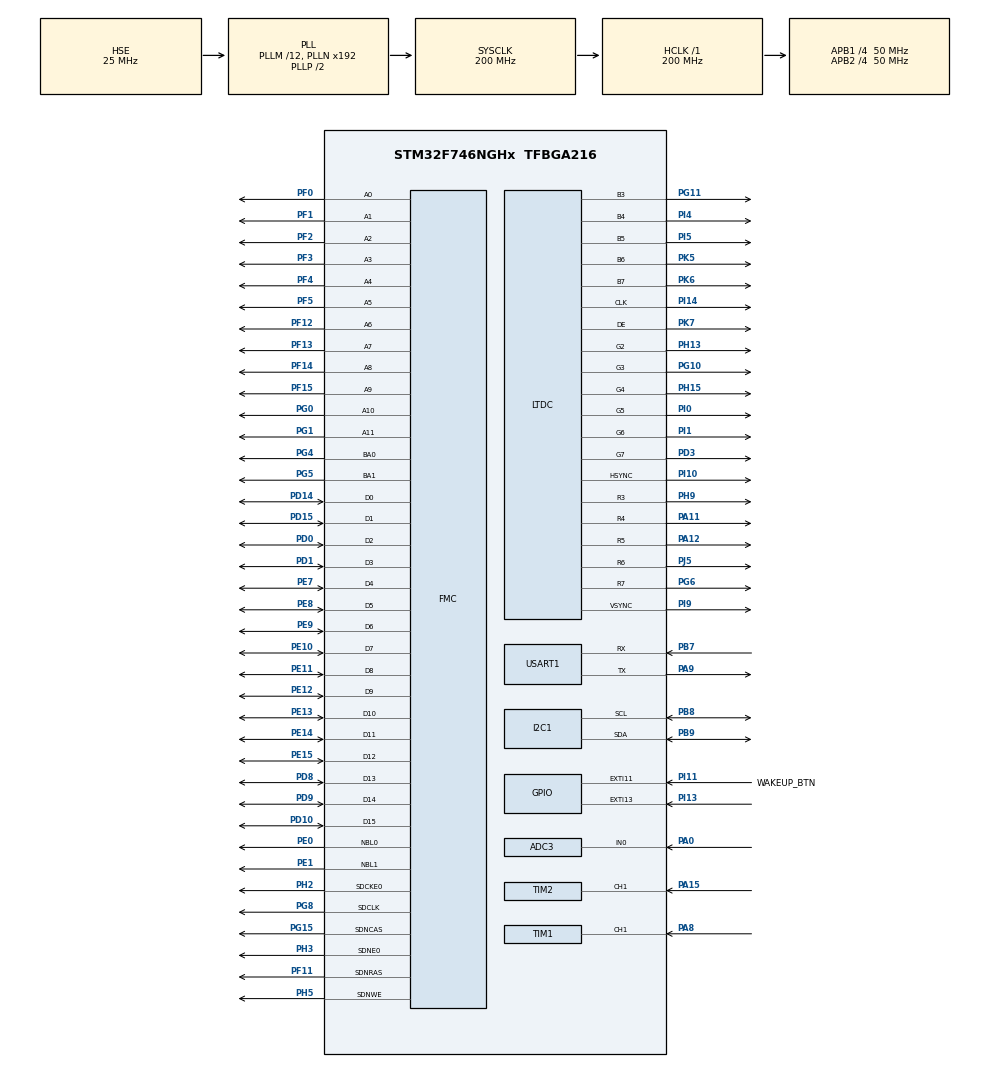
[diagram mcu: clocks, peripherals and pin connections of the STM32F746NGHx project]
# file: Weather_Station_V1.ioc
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ADC3.Channel-0\#ChannelRegularConversion=ADC_CHANNEL_0
ADC3.ClockPrescaler=ADC_CLOCK_SYNC_PCLK_DIV4
ADC3.ContinuousConvMode=ENABLE
ADC3.EOCSelection=ADC_EOC_SEQ_CONV
ADC3.NbrOfConversionFlag=1
ADC3.Rank-0\#ChannelRegularConversion=1
ADC3.SamplingTime-0\#ChannelRegularConversion=ADC_SAMPLETIME_3CYCLES
I2C1.Timing=0x00C0EAFF
Mcu.Family=STM32F7
Mcu.Name=STM32F746NGHx
Mcu.Package=TFBGA216
NVIC.ADC_IRQn=true\:0\:0\:false\:false\:true\:true\:true\:true
NVIC.EXTI15_10_IRQn=true\:0\:0\:false\:false\:true\:true\:true\:true
NVIC.PriorityGroup=NVIC_PRIORITYGROUP_4
NVIC.TIM1_CC_IRQn=true\:3\:0\:true\:false\:true\:true\:true\:true
NVIC.TIM2_IRQn=true\:2\:0\:true\:false\:true\:true\:true\:true
NVIC.TIM3_IRQn=true\:5\:0\:true\:false\:true\:true\:true\:true
NVIC.TIM6_DAC_IRQn=true\:1\:0\:true\:false\:true\:true\:true\:true
NVIC.TIM7_IRQn=true\:4\:0\:true\:false\:true\:true\:true\:true
PA0/WKUP.Signal=ADCx_IN0
PA11.Mode=RGB565
PA11.Signal=LTDC_R4
PA12.Mode=RGB565
PA12.Signal=LTDC_R5
PA13.Mode=Serial_Wire
PA13.Signal=SYS_JTMS-SWDIO
PA14.Mode=Serial_Wire
PA14.Signal=SYS_JTCK-SWCLK
PA15.Signal=S_TIM2_CH1_ETR
PA8.Signal=S_TIM1_CH1
PA9.Mode=Asynchronous
PA9.Signal=USART1_TX
PB7.Mode=Asynchronous
PB7.Signal=USART1_RX
PB8.Mode=I2C
PB8.Signal=I2C1_SCL
PB9.Mode=I2C
PB9.Signal=I2C1_SDA
PC14/OSC32_IN.Mode=LSE-External-Oscillator
PC14/OSC32_IN.Signal=RCC_OSC32_IN
PC15/OSC32_OUT.Mode=LSE-External-Oscillator
PC15/OSC32_OUT.Signal=RCC_OSC32_OUT
PD0.Signal=FMC_D2_DA2
PD1.Signal=FMC_D3_DA3
PD10.Signal=FMC_D15_DA15
PD14.Signal=FMC_D0_DA0
PD15.Signal=FMC_D1_DA1
PD3.Mode=RGB565
PD3.Signal=LTDC_G7
PD8.Signal=FMC_D13_DA13
PD9.Signal=FMC_D14_DA14
PE0.Signal=FMC_NBL0
PE1.Signal=FMC_NBL1
PE10.Signal=FMC_D7_DA7
PE11.Signal=FMC_D8_DA8
PE12.Signal=FMC_D9_DA9
PE13.Signal=FMC_D10_DA10
PE14.Signal=FMC_D11_DA11
PE15.Signal=FMC_D12_DA12
PE7.Signal=FMC_D4_DA4
PE8.Signal=FMC_D5_DA5
PE9.Signal=FMC_D6_DA6
PF0.Signal=FMC_A0
PF1.Signal=FMC_A1
PF11.Signal=FMC_SDNRAS
PF12.Signal=FMC_A6
PF13.Signal=FMC_A7
PF14.Signal=FMC_A8
PF15.Signal=FMC_A9
PF2.Signal=FMC_A2
PF3.Signal=FMC_A3
PF4.Signal=FMC_A4
PF5.Signal=FMC_A5
PG0.Signal=FMC_A10
PG1.Signal=FMC_A11
PG10.Mode=RGB565
PG10.Signal=LTDC_G3
PG11.Mode=RGB565
PG11.Signal=LTDC_B3
PG15.Signal=FMC_SDNCAS
PG4.Signal=FMC_A14_BA0
PG5.Signal=FMC_A15_BA1
PG6.Mode=RGB565
PG6.Signal=LTDC_R7
PG8.Signal=FMC_SDCLK
PH0/OSC_IN.Mode=HSE-External-Oscillator
PH0/OSC_IN.Signal=RCC_OSC_IN
PH1/OSC_OUT.Mode=HSE-External-Oscillator
PH1/OSC_OUT.Signal=RCC_OSC_OUT
PH13.Mode=RGB565
PH13.Signal=LTDC_G2
PH15.Mode=RGB565
PH15.Signal=LTDC_G4
PH2.Mode=SdramChipSelect1_1
PH2.Signal=FMC_SDCKE0
PH3.Mode=SdramChipSelect1_1
PH3.Signal=FMC_SDNE0
PH5.Signal=FMC_SDNWE
PH9.Mode=RGB565
PH9.Signal=LTDC_R3
PI0.Mode=RGB565
PI0.Signal=LTDC_G5
PI1.Mode=RGB565
PI1.Signal=LTDC_G6
PI10.Mode=RGB565
PI10.Signal=LTDC_HSYNC
PI11.GPIO_Label=WAKEUP_BTN
PI11.GPIO_ModeDefaultEXTI=GPIO_MODE_IT_RISING
PI11.GPIO_PuPd=GPIO_NOPULL
PI11.Signal=GPXTI11
PI13.GPIO_ModeDefaultEXTI=GPIO_MODE_IT_RISING_FALLING
PI13.GPIO_PuPd=GPIO_NOPULL
PI13.Signal=GPXTI13
PI14.Mode=RGB565
PI14.Signal=LTDC_CLK
PI4.Mode=RGB565
PI4.Signal=LTDC_B4
PI5.Mode=RGB565
PI5.Signal=LTDC_B5
PI9.Mode=RGB565
PI9.Signal=LTDC_VSYNC
PJ5.Mode=RGB565
PJ5.Signal=LTDC_R6
PK5.Mode=RGB565
PK5.Signal=LTDC_B6
PK6.Mode=RGB565
PK6.Signal=LTDC_B7
PK7.Mode=RGB565
PK7.Signal=LTDC_DE
ProjectManager.HeapSize=0x200
ProjectManager.StackSize=0x400
ProjectManager.TargetToolchain=STM32CubeIDE
RCC.AHBFreq_Value=200000000
RCC.APB1CLKDivider=RCC_HCLK_DIV4
RCC.APB1Freq_Value=50000000
RCC.APB1TimFreq_Value=100000000
RCC.APB2CLKDivider=RCC_HCLK_DIV4
RCC.APB2Freq_Value=50000000
RCC.APB2TimFreq_Value=100000000
RCC.CortexFreq_Value=200000000
RCC.HCLKFreq_Value=200000000
RCC.HSE_VALUE=25000000
RCC.HSI_VALUE=16000000
RCC.PLLM=12
RCC.PLLSAIN=50
RCC.PLLSourceVirtual=RCC_PLLSOURCE_HSE
RCC.RTCClockSelection=RCC_RTCCLKSOURCE_LSE
RCC.SYSCLKFreq_VALUE=200000000
RCC.SYSCLKSource=RCC_SYSCLKSOURCE_PLLCLK
RCC.USBFreq_Value=200000000
RCC.VCOOutputFreq_Value=400000000
SH.ADCx_IN0.0=ADC3_IN0,IN0
SH.FMC_A0.0=FMC_A0,12b-sda1
SH.FMC_A1.0=FMC_A1,12b-sda1
SH.FMC_A10.0=FMC_A10,12b-sda1
SH.FMC_A11.0=FMC_A11,12b-sda1
SH.FMC_A14_BA0.0=FMC_BA0,FourSdramBanks1
SH.FMC_A15_BA1.0=FMC_BA1,FourSdramBanks1
SH.FMC_A2.0=FMC_A2,12b-sda1
SH.FMC_A3.0=FMC_A3,12b-sda1
SH.FMC_A4.0=FMC_A4,12b-sda1
SH.FMC_A5.0=FMC_A5,12b-sda1
SH.FMC_A6.0=FMC_A6,12b-sda1
SH.FMC_A7.0=FMC_A7,12b-sda1
SH.FMC_A8.0=FMC_A8,12b-sda1
SH.FMC_A9.0=FMC_A9,12b-sda1
SH.FMC_D0_DA0.0=FMC_D0,sd-16b-d1
SH.FMC_D10_DA10.0=FMC_D10,sd-16b-d1
SH.FMC_D11_DA11.0=FMC_D11,sd-16b-d1
SH.FMC_D12_DA12.0=FMC_D12,sd-16b-d1
SH.FMC_D13_DA13.0=FMC_D13,sd-16b-d1
SH.FMC_D14_DA14.0=FMC_D14,sd-16b-d1
SH.FMC_D15_DA15.0=FMC_D15,sd-16b-d1
SH.FMC_D1_DA1.0=FMC_D1,sd-16b-d1
SH.FMC_D2_DA2.0=FMC_D2,sd-16b-d1
SH.FMC_D3_DA3.0=FMC_D3,sd-16b-d1
SH.FMC_D4_DA4.0=FMC_D4,sd-16b-d1
SH.FMC_D5_DA5.0=FMC_D5,sd-16b-d1
SH.FMC_D6_DA6.0=FMC_D6,sd-16b-d1
SH.FMC_D7_DA7.0=FMC_D7,sd-16b-d1
SH.FMC_D8_DA8.0=FMC_D8,sd-16b-d1
SH.FMC_D9_DA9.0=FMC_D9,sd-16b-d1
SH.FMC_NBL0.0=FMC_NBL0,Sd2ByteEnable1
SH.FMC_NBL1.0=FMC_NBL1,Sd2ByteEnable1
SH.FMC_SDCLK.0=FMC_SDCLK,12b-sda1
SH.FMC_SDNCAS.0=FMC_SDNCAS,12b-sda1
SH.FMC_SDNRAS.0=FMC_SDNRAS,12b-sda1
SH.FMC_SDNWE.0=FMC_SDNWE,12b-sda1
SH.S_TIM1_CH1.0=TIM1_CH1,Input_Capture1_from_TI1
SH.S_TIM2_CH1_ETR.0=TIM2_CH1,Input_Capture1_from_TI1
TIM1.AutoReloadPreload=TIM_AUTORELOAD_PRELOAD_ENABLE
TIM1.Channel-Input_Capture1_from_TI1=TIM_CHANNEL_1
TIM1.Period=9999
TIM1.Prescaler=9999
TIM2.AutoReloadPreload=TIM_AUTORELOAD_PRELOAD_ENABLE
TIM2.Channel-Input_Capture1_from_TI1=TIM_CHANNEL_1
TIM2.Period=9999
TIM2.Prescaler=9999
TIM3.Period=9999
TIM3.Prescaler=299
TIM6.AutoReloadPreload=TIM_AUTORELOAD_PRELOAD_ENABLE
TIM6.Period=9999
TIM6.Prescaler=9999
TIM7.AutoReloadPreload=TIM_AUTORELOAD_PRELOAD_ENABLE
TIM7.Period=9999
TIM7.Prescaler=4999
USART1.VirtualMode-Asynchronous=VM_ASYNC
VP_DMA2D_VS_DMA2D.Mode=DMA2D_Activate
VP_RTC_VS_RTC_Activate.Mode=RTC_Enabled
VP_TIM1_VS_ClockSourceINT.Mode=Internal
VP_TIM2_VS_ClockSourceINT.Mode=Internal
VP_TIM3_VS_ClockSourceINT.Mode=Internal
VP_TIM6_VS_ClockSourceINT.Mode=Enable_Timer
VP_TIM7_VS_ClockSourceINT.Mode=Enable_Timer
board=STM32F746G-DISCO

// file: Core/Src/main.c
/* USER CODE BEGIN Header */
/**
  ******************************************************************************
  * @file           : main.c
  * @brief          : Main program body
  ******************************************************************************
  * @attention
  *
  * Copyright (c) 2025 STMicroelectronics.
  * All rights reserved.
  *
  ******************************************************************************
  */
/* USER CODE END Header */
#include "main.h"
#include "adc.h"
#include "dma2d.h"
#include "i2c.h"
#include "ltdc.h"
#include "rtc.h"
#include "tim.h"
#include "usart.h"
#include "gpio.h"
#include "fmc.h"

/* USER CODE BEGIN Includes */
#include <string.h>
#include <stdio.h>
#include <stdbool.h>
#include "screen.h"
#include "Read_Sensors_THP.h"
#include "data.h"
#include "stm32746g_discovery_ts.h"
#include "Lecture_anenometer.h"
#include "Lecture_girouette.h"
#include "Lecture_pluviometre.h"
/* USER CODE END Includes */

/* USER CODE BEGIN PV */
volatile int Flag_Tim6 = 0;
volatile int Flag_Tim7 = 0;
volatile int Flag_Tim2 = 0;
volatile int Flag_Tim1 = 0;
volatile int Flag_Tim3 = 0;
volatile uint8_t Flag_Touch = 0;
int current_page = 0;
volatile meteo_data_t current_data;
volatile meteo_data_t min_data[60]; //1 donnée par seconde pour la dernière minute
//on garde une donnée sur 60 dans la 2nd liste pour économiser mémoire
volatile meteo_data_t day_data[1440]; //1 donnée par minute pour les dernières 24h
volatile float vitesse_vent = 0.0;
volatile GirouetteData_t girouette_data;  //  Données girouette
volatile PluviometreData_t pluie_data; //  Données pluviometre
int data_index;
volatile int idle_time;
/* USER CODE END PV */

void SystemClock_Config(void);
/* USER CODE BEGIN PFP */
#ifdef __GNUC__
#define PUTCHAR_PROTOTYPE int __io_putchar(int ch)
#else
#define PUTCHAR_PROTOTYPE int fputc(int ch, FILE *f)
#endif
void RTC_Init();
/* USER CODE END PFP */

int main(void)
{

  /* MCU Configuration--------------------------------------------------------*/

  /* Reset of all peripherals, Initializes the Flash interface and the Systick. */
  HAL_Init();

  /* Configure the system clock */
  SystemClock_Config();

  /* Initialize all configured peripherals */
  MX_GPIO_Init();
  MX_I2C1_Init();
  MX_USART1_UART_Init();
  MX_TIM6_Init();
  MX_TIM2_Init();
  MX_DMA2D_Init();
  MX_FMC_Init();
  MX_LTDC_Init();
  MX_RTC_Init();
  MX_TIM1_Init();
  MX_TIM3_Init();
  MX_TIM7_Init();
  MX_ADC3_Init();
  /* USER CODE BEGIN 2 */
    /* LCD Initialization */

  	  init_screen();
    // Initialisation des capteurs (remplace votre code d'init dans Read_Sensors_THP.c)
    SensorsTHP_Init();
    Anemometer_Init();          // Anémomètre
    Girouette_Init();           // Girouette
    Pluviometre_Init();   // pluviometre
    RTC_Init();
    idle_time = 0;

    //Initialisation des données
    current_data = (meteo_data_t){0};
    data_index = 0;
    meteo_clear_buffer(min_data, 60);
    meteo_clear_buffer(day_data, 1440);

    /* Start TIM6 interrupt */
    HAL_TIM_Base_Start_IT(&htim6);
    HAL_TIM_Base_Start_IT(&htim7);
    HAL_TIM_Base_Start_IT(&htim3);
    HAL_TIM_IC_Start_IT(&htim1, TIM_CHANNEL_1);
    HAL_TIM_IC_Start_IT(&htim2, TIM_CHANNEL_1);
    //  Démarrer la girouette (ADC en continu)
        Girouette_Start_Conversion();
  /* USER CODE END 2 */

  /* Infinite loop */
  /* USER CODE BEGIN WHILE */
    while (1)
    {

        if (Flag_Tim3)
        {
            Flag_Tim3 = 0;

            TS_StateTypeDef ts;
            BSP_TS_GetState(&ts);

            if (ts.touchDetected)
            {
                uint16_t x = ts.touchX[0];
                uint16_t y = ts.touchY[0];

                idle_time = 0;
                current_page = handle_touch(x, y, current_page);
            }
            else
            {
                idle_time++;
            }
        }
        else if(Flag_Touch == 1)
        {
        	if (idle_time >= 2000U){ // vérifie est ce qu'on attient la durée de 1 min pour lancer la routine
        	Flag_Touch = 0;
            idle_time = 0;

            __HAL_TIM_SET_COUNTER(&htim3, 0);
            __HAL_TIM_SET_COUNTER(&htim6, 0);
            __HAL_TIM_SET_COUNTER(&htim7, 0);

            HAL_TIM_Base_Start_IT(&htim6);
            HAL_TIM_Base_Start_IT(&htim7);
            HAL_TIM_Base_Start_IT(&htim3);
            HAL_TIM_IC_Start_IT(&htim1, TIM_CHANNEL_1);

            // Réinitialisez le touch screen
            BSP_TS_Init(BSP_LCD_GetXSize(), BSP_LCD_GetYSize());
            // Redessinez l'écran
            init_screen();
            update_screen(current_page);}
        	else // idle_time < durée (60s), on laisse le système dans son mode normal
        		{idle_time = 0;
        		Flag_Touch = 0;}
        }
        else if (Flag_Tim7)
        {
            update_screen(current_page);
            Flag_Tim7 = 0;
        }
    	else if (Flag_Tim6)
        {
            // Lecture des capteurs température/humidité/pression
        	SensorsTHP_ReadAll();
            printf("Temp: %.2f°C | Hum: %.2f%% | Press: %.2fhPa\r\n",
                   sensor_data.temperature,
                   sensor_data.humidity,
                   sensor_data.pressure);

            // Lecture de la girouette
            Girouette_Read_Direction(&girouette_data);
            // Mettre à jour les données courantes
            current_data.vent_direction = girouette_data.angle_deg;
            printf("Direction de vent: %s (ADC=%u, Angle=%.1f°)\r\nVitesse du vent: %.2fkm/h \r\n",
                   girouette_data.direction_courte,
                   girouette_data.valeur_adc,
                   girouette_data.angle_deg,
				   vitesse_vent);
            Flag_Tim6 = 0;
            // Mise à jour de l'écran
            create_data();
            data_index++;
            if (data_index >= 60)
            {
                data_index = 0;
                // Une fois par minute
                meteo_append(day_data, 1440, &current_data);
            }
            meteo_append(min_data, 60, &current_data);
        }
    	else if (Flag_Tim2)  // Pluviomètre
    	{
    	    // Mettre à jour les périodes du pluviomètre
    	    Pluviometre_Update_Periodes();

    	    // Lire les données courantes
    	    Lecture_pluviometre(&pluie_data);

    	    // Mettre à jour les données courantes (ex: pluie_1h_mm)
    	    current_data.pluie = pluie_data.pluie_1h_mm;  // ou pluie_data.pluie_1h_mm

    	    // Debug (optionnel)
    	    if (pluie_data.nouvelle_mesure)
    	    {
    	        printf("Pluie: %.2f mm/h\r\n", pluie_data.pluie_1h_mm);
    	    }

    	    Flag_Tim2 = 0;
    	}
        else if (Flag_Tim1)
        {
            Lecture_anenometer(&vitesse_vent);
            Flag_Tim1 = 0;
        }
        else
        {
            if(idle_time >= 2000U)  // 60 secondes pour que le système sera en Mode Stop
            {
                // Entrez en mode STOP
                HAL_SuspendTick();
                HAL_PWR_EnterSTOPMode(PWR_MAINREGULATOR_ON, PWR_STOPENTRY_WFI);
	 			HAL_ResumeTick();
		        SystemClock_Config();       // reconfig horloge après STOP
            }
            else
            {
            	// Sinon, Entrez en mode STOP
                HAL_PWR_EnterSLEEPMode(PWR_MAINREGULATOR_ON, PWR_SLEEPENTRY_WFI);
            }
   	    }
    }
    /* USER CODE END WHILE */

}

void SystemClock_Config(void)
{
  RCC_OscInitTypeDef RCC_OscInitStruct = {0};
  RCC_ClkInitTypeDef RCC_ClkInitStruct = {0};

  /** Configure LSE Drive Capability
  */
  HAL_PWR_EnableBkUpAccess();
  __HAL_RCC_LSEDRIVE_CONFIG(RCC_LSEDRIVE_LOW);

  /** Configure the main internal regulator output voltage
  */
  __HAL_RCC_PWR_CLK_ENABLE();
  __HAL_PWR_VOLTAGESCALING_CONFIG(PWR_REGULATOR_VOLTAGE_SCALE1);

  /** Initializes the RCC Oscillators according to the specified parameters
  * in the RCC_OscInitTypeDef structure.
  */
  RCC_OscInitStruct.OscillatorType = RCC_OSCILLATORTYPE_HSE|RCC_OSCILLATORTYPE_LSE;
  RCC_OscInitStruct.HSEState = RCC_HSE_ON;
  RCC_OscInitStruct.LSEState = RCC_LSE_ON;
  RCC_OscInitStruct.PLL.PLLState = RCC_PLL_ON;
  RCC_OscInitStruct.PLL.PLLSource = RCC_PLLSOURCE_HSE;
  RCC_OscInitStruct.PLL.PLLM = 12;
  RCC_OscInitStruct.PLL.PLLN = 192;
  RCC_OscInitStruct.PLL.PLLP = RCC_PLLP_DIV2;
  RCC_OscInitStruct.PLL.PLLQ = 2;
  if (HAL_RCC_OscConfig(&RCC_OscInitStruct) != HAL_OK)
  {
    Error_Handler();
  }

  /** Activate the Over-Drive mode
  */
  if (HAL_PWREx_EnableOverDrive() != HAL_OK)
  {
    Error_Handler();
  }

  /** Initializes the CPU, AHB and APB buses clocks
  */
  RCC_ClkInitStruct.ClockType = RCC_CLOCKTYPE_HCLK|RCC_CLOCKTYPE_SYSCLK
                              |RCC_CLOCKTYPE_PCLK1|RCC_CLOCKTYPE_PCLK2;
  RCC_ClkInitStruct.SYSCLKSource = RCC_SYSCLKSOURCE_PLLCLK;
  RCC_ClkInitStruct.AHBCLKDivider = RCC_SYSCLK_DIV1;
  RCC_ClkInitStruct.APB1CLKDivider = RCC_HCLK_DIV4;
  RCC_ClkInitStruct.APB2CLKDivider = RCC_HCLK_DIV4;

  if (HAL_RCC_ClockConfig(&RCC_ClkInitStruct, FLASH_LATENCY_6) != HAL_OK)
  {
    Error_Handler();
  }
}

/* USER CODE BEGIN 4 */

/**
  * @brief Fonction printf redirigée vers UART
  */
PUTCHAR_PROTOTYPE
{
  uint8_t c = (uint8_t)ch;
  HAL_UART_Transmit(&huart1, &c, 1, HAL_MAX_DELAY);
  return ch;
}

void RTC_Init() {
	if (HAL_RTCEx_BKUPRead(&hrtc, RTC_BKP_DR0) != 0xBEEF)
	{
		RTC_TimeTypeDef sTime = {0};
		RTC_DateTypeDef sDate = {0};

		sTime.Hours   = 12;
		sTime.Minutes = 0;
		sTime.Seconds = 0;

		sDate.Year  = 25;               // 2025
		sDate.Month = RTC_MONTH_JANUARY;
		sDate.Date  = 1;
		sDate.WeekDay = RTC_WEEKDAY_WEDNESDAY;

		HAL_RTC_SetTime(&hrtc, &sTime, RTC_FORMAT_BIN);
		HAL_RTC_SetDate(&hrtc, &sDate, RTC_FORMAT_BIN);

		HAL_RTCEx_BKUPWrite(&hrtc, RTC_BKP_DR0, 0xBEEF);
	}
}

/* USER CODE END 4 */

void Error_Handler(void)
{
  __disable_irq();
  while (1)
  {
  }
}
